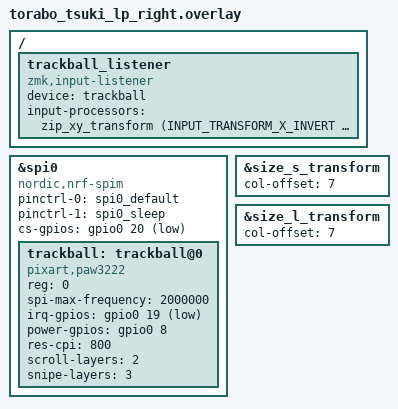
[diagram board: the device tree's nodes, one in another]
#include "torabo_tsuki_lp.dtsi"
#include <input/processors.dtsi>
#include <dt-bindings/zmk/input_transform.h>

&spi0 {
    status = "okay";
    compatible = "nordic,nrf-spim";
    pinctrl-0 = <&spi0_default>;
    pinctrl-1 = <&spi0_sleep>;
    pinctrl-names = "default", "sleep";
    cs-gpios = <&gpio0 20 GPIO_ACTIVE_LOW>;

    trackball: trackball@0 {
        status = "okay";
        compatible = "pixart,paw3222";
        reg = <0>;
        spi-max-frequency = <2000000>;
        irq-gpios = <&gpio0 19 GPIO_ACTIVE_LOW>;
        power-gpios = <&gpio0 8 (GPIO_ACTIVE_HIGH | NRF_GPIO_DRIVE_H1)>;

        res-cpi = <800>;
        scroll-layers = <2>;
        snipe-layers = <3>;
    };
};

/ {
    trackball_listener: trackball_listener {
        compatible = "zmk,input-listener";
        device = <&trackball>;
    };
};

&trackball_listener {
    input-processors = <&zip_xy_transform (INPUT_TRANSFORM_X_INVERT | INPUT_TRANSFORM_Y_INVERT)>;
};

&size_s_transform {
    col-offset = <7>;
};

// &size_m_transform {
//     col-offset = <7>;
// };

&size_l_transform {
    col-offset = <7>;
};
